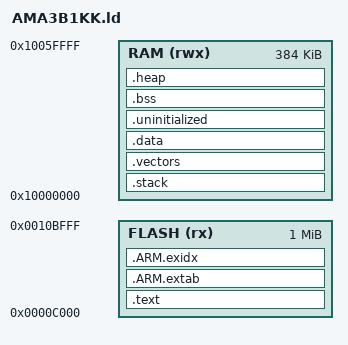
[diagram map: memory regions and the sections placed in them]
/******************************************************************************
 * @file     gcc_arm.ld
 * @brief    GNU Linker Script for Cortex-M based device
 * @version  V2.0.0
 * @date     21. May 2019
 ******************************************************************************/
/*
 * Copyright (c) 2009-2019 Arm Limited. All rights reserved.
 *
 * SPDX-License-Identifier: Apache-2.0
 *
 * Licensed under the Apache License, Version 2.0 (the License); you may
 * not use this file except in compliance with the License.
 * You may obtain a copy of the License at
 *
 * www.apache.org/licenses/LICENSE-2.0
 *
 * Unless required by applicable law or agreed to in writing, software
 * distributed under the License is distributed on an AS IS BASIS, WITHOUT
 * WARRANTIES OR CONDITIONS OF ANY KIND, either express or implied.
 * See the License for the specific language governing permissions and
 * limitations under the License.
 */

FLASH_START = 0x0000C000;
FLASH_SIZE  = 0x00100000;
RAM_START   = 0x10000000;
RAM_SIZE    = 0x00060000;
STACK_SIZE  = 0x00001000;
VECTORS_SIZE = 0x100;

MEMORY
{
  FLASH (rx)  : ORIGIN = FLASH_START, LENGTH = FLASH_SIZE
  RAM   (rwx) : ORIGIN = RAM_START, LENGTH = RAM_SIZE
}

/* Linker script to place sections and symbol values. Should be used together
 * with other linker script that defines memory regions FLASH and RAM.
 * It references following symbols, which must be defined in code:
 *   Reset_Handler : Entry of reset handler
 *
 * It defines following symbols, which code can use without definition:
 *   __exidx_start
 *   __exidx_end
 *   __etext
 *   __data_start__
 *   __preinit_array_start
 *   __preinit_array_end
 *   __init_array_start
 *   __init_array_end
 *   __fini_array_start
 *   __fini_array_end
 *   __data_end__
 *   __bss_start__
 *   __bss_end__
 *   __end__
 *   end
 *   __HeapLimit
 *   __StackLimit
 *   __StackTop
 *   __stack
 */
ENTRY(Reset_Handler)

SECTIONS
{
  .text :
  {
    KEEP(*(.isr_vector))
    KEEP(*(.patch))
    *(.text*)

    KEEP(*(.init))
    KEEP(*(.fini))

    /* .ctors */
    *crtbegin.o(.ctors)
    *crtbegin?.o(.ctors)
    *(EXCLUDE_FILE(*crtend?.o *crtend.o) .ctors)
    *(SORT(.ctors.*))
    *(.ctors)

    /* .dtors */
    *crtbegin.o(.dtors)
    *crtbegin?.o(.dtors)
    *(EXCLUDE_FILE(*crtend?.o *crtend.o) .dtors)
    *(SORT(.dtors.*))
    *(.dtors)

    *(.rodata*)

    KEEP(*(.eh_frame*))
  } > FLASH

  .ARM.extab :
  {
    *(.ARM.extab* .gnu.linkonce.armextab.*)
  } > FLASH

  __exidx_start = .;
  .ARM.exidx :
  {
    *(.ARM.exidx* .gnu.linkonce.armexidx.*)
  } > FLASH
  __exidx_end = .;

  __etext = .;

  .stack (NOLOAD):
  {
      . = ALIGN(8);
      *(.stack*)
      . = . + STACK_SIZE;
      . = ALIGN(8);
        __StackTop = .;
  } > RAM
  __StackLimit = RAM_START;
  PROVIDE(__stack = __StackTop - 8);

  .vectors (NOLOAD):
  {
    __vectors_start__ = .;
    *(.vectors*)
    . += VECTORS_SIZE;
    __vectors_end__ = .;
  } > RAM

  .data : AT (__etext)
  {
    __data_start__ = .;
    *(vtable)
    *(.data*)

    . = ALIGN(8);
    /* preinit data */
    PROVIDE_HIDDEN (__preinit_array_start = .);
    KEEP(*(.preinit_array))
    PROVIDE_HIDDEN (__preinit_array_end = .);

    . = ALIGN(8);
    /* init data */
    PROVIDE_HIDDEN (__init_array_start = .);
    KEEP(*(SORT(.init_array.*)))
    KEEP(*(.init_array))
    PROVIDE_HIDDEN (__init_array_end = .);


    . = ALIGN(8);
    /* finit data */
    PROVIDE_HIDDEN (__fini_array_start = .);
    KEEP(*(SORT(.fini_array.*)))
    KEEP(*(.fini_array))
    PROVIDE_HIDDEN (__fini_array_end = .);

    KEEP(*(.jcr*))
    . = ALIGN(8);
    __data_end__ = .;

  } > RAM

  .uninitialized (NOLOAD):
  {
      . = ALIGN(32);
      __uninitialized_start = .;
      *(.uninitialized)
      KEEP(*(.keep.uninitialized))
      . = ALIGN(32);
      __uninitialized_end = .;
  } > RAM

  .bss :
  {
    . = ALIGN(8);
    __bss_start__ = .;
    *(.bss*)
    *(COMMON)
    . = ALIGN(8);
    __bss_end__ = .;
  } > RAM

  .heap (COPY):
  {
    __end__ = .;
    PROVIDE(end = .);
    *(.heap*)
    __HeapBase = .;
    . = ORIGIN(RAM) + LENGTH(RAM);
    __HeapLimit = .;
  } > RAM
}
PROVIDE(HEAP_SIZE = __HeapLimit - __HeapBase);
